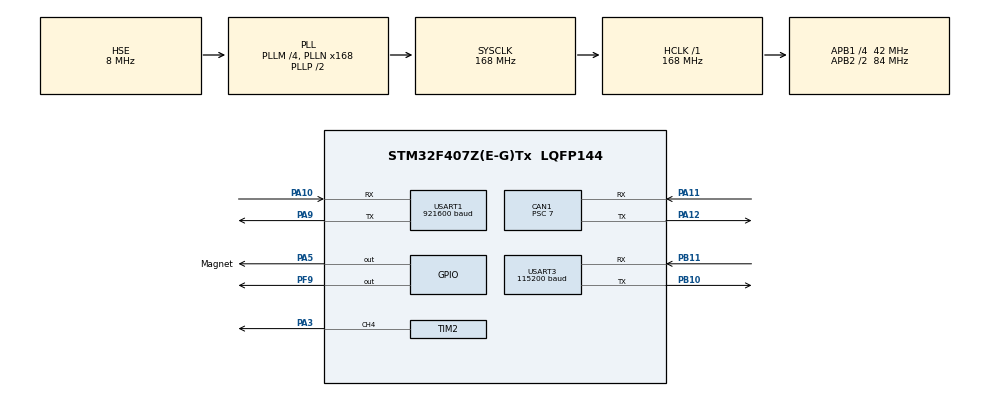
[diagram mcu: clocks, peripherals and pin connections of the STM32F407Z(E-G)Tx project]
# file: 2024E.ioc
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CAN1.ABOM=ENABLE
CAN1.BS1=CAN_BS1_3TQ
CAN1.BS2=CAN_BS2_2TQ
CAN1.CalculateBaudRate=999999
CAN1.CalculateTimeBit=1000
CAN1.CalculateTimeQuantum=166.66666666666669
CAN1.NART=ENABLE
CAN1.Prescaler=7
Dma.Request0=USART3_TX
Dma.USART3_TX.0.Direction=DMA_MEMORY_TO_PERIPH
Dma.USART3_TX.0.FIFOMode=DMA_FIFOMODE_DISABLE
Dma.USART3_TX.0.Instance=DMA1_Stream3
Dma.USART3_TX.0.MemDataAlignment=DMA_MDATAALIGN_BYTE
Dma.USART3_TX.0.MemInc=DMA_MINC_ENABLE
Dma.USART3_TX.0.Mode=DMA_NORMAL
Dma.USART3_TX.0.PeriphDataAlignment=DMA_PDATAALIGN_BYTE
Dma.USART3_TX.0.PeriphInc=DMA_PINC_DISABLE
Dma.USART3_TX.0.Priority=DMA_PRIORITY_LOW
FREERTOS.Tasks01=defaultTask,24,128,StartDefaultTask,Default,NULL,Dynamic,NULL,NULL;ReceiveTask,24,256,StartReceiveTask,As external,NULL,Dynamic,NULL,NULL;MotorTask,24,256,StartMotorTask,As external,NULL,Dynamic,NULL,NULL;ScreenTask,24,256,StartScreenTask,As external,NULL,Dynamic,NULL,NULL;Sg90Task,32,128,StartSg90Task,As external,NULL,Dynamic,NULL,NULL
Mcu.Family=STM32F4
Mcu.Name=STM32F407Z(E-G)Tx
Mcu.Package=LQFP144
NVIC.CAN1_RX0_IRQn=true\:5\:0\:false\:false\:true\:true\:true\:true\:true
NVIC.CAN1_RX1_IRQn=true\:5\:0\:false\:false\:true\:true\:true\:true\:true
NVIC.DMA1_Stream3_IRQn=true\:5\:0\:false\:false\:true\:true\:false\:true\:true
NVIC.PriorityGroup=NVIC_PRIORITYGROUP_4
NVIC.TIM8_TRG_COM_TIM14_IRQn=true\:15\:0\:false\:false\:true\:false\:false\:true\:true
NVIC.TimeBase=TIM8_TRG_COM_TIM14_IRQn
NVIC.TimeBaseIP=TIM14
NVIC.USART1_IRQn=true\:5\:0\:false\:false\:true\:true\:true\:true\:true
NVIC.USART3_IRQn=true\:5\:0\:false\:false\:true\:true\:true\:true\:true
PA10.Mode=Asynchronous
PA10.Signal=USART1_RX
PA11.Mode=CAN_Activate
PA11.Signal=CAN1_RX
PA12.Mode=CAN_Activate
PA12.Signal=CAN1_TX
PA13.Mode=Serial_Wire
PA13.Signal=SYS_JTMS-SWDIO
PA14.Mode=Serial_Wire
PA14.Signal=SYS_JTCK-SWCLK
PA3.Signal=S_TIM2_CH4
PA5.GPIO_Label=Magnet
PA5.GPIO_PuPd=GPIO_PULLUP
PA5.PinState=GPIO_PIN_SET
PA5.Signal=GPIO_Output
PA9.Mode=Asynchronous
PA9.Signal=USART1_TX
PB10.Mode=Asynchronous
PB10.Signal=USART3_TX
PB11.Mode=Asynchronous
PB11.Signal=USART3_RX
PC14-OSC32_IN.Mode=LSE-External-Oscillator
PC14-OSC32_IN.Signal=RCC_OSC32_IN
PC15-OSC32_OUT.Mode=LSE-External-Oscillator
PC15-OSC32_OUT.Signal=RCC_OSC32_OUT
PF9.GPIO_PuPd=GPIO_PULLUP
PF9.Signal=GPIO_Output
PH0-OSC_IN.Mode=HSE-External-Oscillator
PH0-OSC_IN.Signal=RCC_OSC_IN
PH1-OSC_OUT.Mode=HSE-External-Oscillator
PH1-OSC_OUT.Signal=RCC_OSC_OUT
ProjectManager.HeapSize=0x200
ProjectManager.StackSize=0x400
ProjectManager.TargetToolchain=CMake
RCC.48MHZClocksFreq_Value=84000000
RCC.AHBFreq_Value=168000000
RCC.APB1CLKDivider=RCC_HCLK_DIV4
RCC.APB1Freq_Value=42000000
RCC.APB1TimFreq_Value=84000000
RCC.APB2CLKDivider=RCC_HCLK_DIV2
RCC.APB2Freq_Value=84000000
RCC.APB2TimFreq_Value=168000000
RCC.CortexFreq_Value=168000000
RCC.HCLKFreq_Value=168000000
RCC.HSE_VALUE=8000000
RCC.HSI_VALUE=16000000
RCC.PLLM=4
RCC.PLLN=168
RCC.PLLSourceVirtual=RCC_PLLSOURCE_HSE
RCC.SYSCLKFreq_VALUE=168000000
RCC.SYSCLKSource=RCC_SYSCLKSOURCE_PLLCLK
RCC.VCOOutputFreq_Value=336000000
SH.S_TIM2_CH4.0=TIM2_CH4,PWM Generation4 CH4
TIM2.AutoReloadPreload=TIM_AUTORELOAD_PRELOAD_ENABLE
TIM2.Channel-PWM\ Generation4\ CH4=TIM_CHANNEL_4
TIM2.OCPolarity_4=TIM_OCPOLARITY_HIGH
TIM2.Period=19999
TIM2.Prescaler=83
TIM2.Pulse-PWM\ Generation4\ CH4=0
USART1.BaudRate=921600
USART1.VirtualMode=VM_ASYNC
USART3.BaudRate=115200
USART3.VirtualMode=VM_ASYNC
VP_FREERTOS_VS_CMSIS_V2.Mode=CMSIS_V2
VP_SYS_VS_tim14.Mode=TIM14
board=custom

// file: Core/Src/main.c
/* USER CODE BEGIN Header */
/**
  ******************************************************************************
  * @file           : main.c
  * @brief          : Main program body
  ******************************************************************************
  * @attention
  *
  * Copyright (c) 2026 STMicroelectronics.
  * All rights reserved.
  *
  * This software is licensed under terms that can be found in the LICENSE file
  * in the root directory of this software component.
  * If no LICENSE file comes with this software, it is provided AS-IS.
  *
  ******************************************************************************
  */
/* USER CODE END Header */
#include "main.h"
#include "cmsis_os.h"
#include "can.h"
#include "dma.h"
#include "tim.h"
#include "usart.h"
#include "gpio.h"

/* USER CODE BEGIN Includes */
#include <stdio.h>
#include "SG90/sg90.h"
#include "Test/test.h"
/* USER CODE END Includes */

void SystemClock_Config(void);
void MX_FREERTOS_Init(void);

int main(void)
{

  /* MCU Configuration--------------------------------------------------------*/

  /* Reset of all peripherals, Initializes the Flash interface and the Systick. */
  HAL_Init();

  /* Configure the system clock */
  SystemClock_Config();

  /* Initialize all configured peripherals */
  MX_GPIO_Init();
  MX_DMA_Init();
  MX_CAN1_Init();
  MX_TIM2_Init();
  MX_USART1_UART_Init();
  MX_USART3_UART_Init();
  /* USER CODE BEGIN 2 */
  HAL_Delay(100);

  /* USER CODE END 2 */

  /* Init scheduler */
  osKernelInitialize();  /* Call init function for freertos objects (in cmsis_os2.c) */
  MX_FREERTOS_Init();

  /* Start scheduler */
  osKernelStart();

  /* We should never get here as control is now taken by the scheduler */

  /* Infinite loop */
  while (1)
  {

  }
}

void SystemClock_Config(void)
{
  RCC_OscInitTypeDef RCC_OscInitStruct = {0};
  RCC_ClkInitTypeDef RCC_ClkInitStruct = {0};

  /** Configure the main internal regulator output voltage
  */
  __HAL_RCC_PWR_CLK_ENABLE();
  __HAL_PWR_VOLTAGESCALING_CONFIG(PWR_REGULATOR_VOLTAGE_SCALE1);

  /** Initializes the RCC Oscillators according to the specified parameters
  * in the RCC_OscInitTypeDef structure.
  */
  RCC_OscInitStruct.OscillatorType = RCC_OSCILLATORTYPE_HSE;
  RCC_OscInitStruct.HSEState = RCC_HSE_ON;
  RCC_OscInitStruct.PLL.PLLState = RCC_PLL_ON;
  RCC_OscInitStruct.PLL.PLLSource = RCC_PLLSOURCE_HSE;
  RCC_OscInitStruct.PLL.PLLM = 4;
  RCC_OscInitStruct.PLL.PLLN = 168;
  RCC_OscInitStruct.PLL.PLLP = RCC_PLLP_DIV2;
  RCC_OscInitStruct.PLL.PLLQ = 4;
  if (HAL_RCC_OscConfig(&RCC_OscInitStruct) != HAL_OK)
  {
    Error_Handler();
  }

  /** Initializes the CPU, AHB and APB buses clocks
  */
  RCC_ClkInitStruct.ClockType = RCC_CLOCKTYPE_HCLK|RCC_CLOCKTYPE_SYSCLK
                              |RCC_CLOCKTYPE_PCLK1|RCC_CLOCKTYPE_PCLK2;
  RCC_ClkInitStruct.SYSCLKSource = RCC_SYSCLKSOURCE_PLLCLK;
  RCC_ClkInitStruct.AHBCLKDivider = RCC_SYSCLK_DIV1;
  RCC_ClkInitStruct.APB1CLKDivider = RCC_HCLK_DIV4;
  RCC_ClkInitStruct.APB2CLKDivider = RCC_HCLK_DIV2;

  if (HAL_RCC_ClockConfig(&RCC_ClkInitStruct, FLASH_LATENCY_5) != HAL_OK)
  {
    Error_Handler();
  }
}

/* USER CODE BEGIN 4 */
int __io_putchar(int ch,FILE *f)
{
  uint8_t temp[1]={ch};
  HAL_UART_Transmit(&huart3,temp,1,0xFFFF);
  return ch;
}
/* USER CODE END 4 */

void HAL_TIM_PeriodElapsedCallback(TIM_HandleTypeDef *htim)
{
  if (htim->Instance == TIM14)
  {
    HAL_IncTick();
  }
}

void Error_Handler(void)
{
  /* USER CODE BEGIN Error_Handler_Debug */
  /* User can add his own implementation to report the HAL error return state */
  __disable_irq();
  while (1)
  {
    HAL_GPIO_TogglePin(GPIOF, GPIO_PIN_9);
    osDelay(500);
  }
  /* USER CODE END Error_Handler_Debug */
}

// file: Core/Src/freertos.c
/* USER CODE BEGIN Header */
/**
  ******************************************************************************
  * File Name          : freertos.c
  * Description        : Code for freertos applications
  ******************************************************************************
  * @attention
  *
  * Copyright (c) 2026 STMicroelectronics.
  * All rights reserved.
  *
  * This software is licensed under terms that can be found in the LICENSE file
  * in the root directory of this software component.
  * If no LICENSE file comes with this software, it is provided AS-IS.
  *
  ******************************************************************************
  */
/* USER CODE END Header */

#include "FreeRTOS.h"
#include "task.h"
#include "main.h"
#include "cmsis_os.h"

/* Definitions for defaultTask */
osThreadId_t defaultTaskHandle;
const osThreadAttr_t defaultTask_attributes = {
  .name = "defaultTask",
  .stack_size = 128 * 4,
  .priority = (osPriority_t) osPriorityNormal,
};
/* Definitions for ReceiveTask */
osThreadId_t ReceiveTaskHandle;
const osThreadAttr_t ReceiveTask_attributes = {
  .name = "ReceiveTask",
  .stack_size = 256 * 4,
  .priority = (osPriority_t) osPriorityNormal,
};
/* Definitions for MotorTask */
osThreadId_t MotorTaskHandle;
const osThreadAttr_t MotorTask_attributes = {
  .name = "MotorTask",
  .stack_size = 256 * 4,
  .priority = (osPriority_t) osPriorityNormal,
};
/* Definitions for ScreenTask */
osThreadId_t ScreenTaskHandle;
const osThreadAttr_t ScreenTask_attributes = {
  .name = "ScreenTask",
  .stack_size = 256 * 4,
  .priority = (osPriority_t) osPriorityNormal,
};
/* Definitions for Sg90Task */
osThreadId_t Sg90TaskHandle;
const osThreadAttr_t Sg90Task_attributes = {
  .name = "Sg90Task",
  .stack_size = 128 * 4,
  .priority = (osPriority_t) osPriorityAboveNormal,
};

void StartDefaultTask(void *argument);
extern void StartReceiveTask(void *argument);
extern void StartMotorTask(void *argument);
extern void StartScreenTask(void *argument);
extern void StartSg90Task(void *argument);

void MX_FREERTOS_Init(void); /* (MISRA C 2004 rule 8.1) */

void MX_FREERTOS_Init(void) {

  /* Create the thread(s) */
  /* creation of defaultTask */
  defaultTaskHandle = osThreadNew(StartDefaultTask, NULL, &defaultTask_attributes);

  /* creation of ReceiveTask */
  ReceiveTaskHandle = osThreadNew(StartReceiveTask, NULL, &ReceiveTask_attributes);

  /* creation of MotorTask */
  MotorTaskHandle = osThreadNew(StartMotorTask, NULL, &MotorTask_attributes);

  /* creation of ScreenTask */
  ScreenTaskHandle = osThreadNew(StartScreenTask, NULL, &ScreenTask_attributes);

  /* creation of Sg90Task */
  Sg90TaskHandle = osThreadNew(StartSg90Task, NULL, &Sg90Task_attributes);

  /* USER CODE BEGIN RTOS_THREADS */
  //vTaskSuspend(defaultTaskHandle);  // Suspend the default task to prevent it from running
  //vTaskSuspend(ReceiveTaskHandle);  // Suspend the Receive task to prevent it from running
  //vTaskSuspend(MotorTaskHandle);    // Suspend the Motor task to prevent it from running
  //vTaskSuspend(ScreenTaskHandle);   // Suspend the Screen task to prevent it from running
  /* add threads, ... */
  /* USER CODE END RTOS_THREADS */

}

void StartDefaultTask(void *argument)
{
  for(;;)
  {
    osDelay(1);
  }
}
